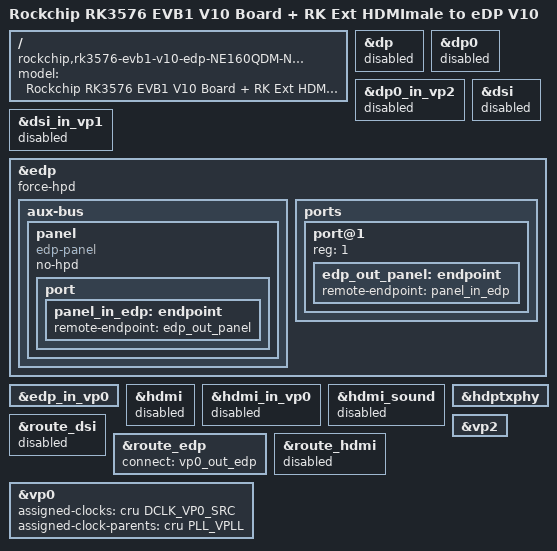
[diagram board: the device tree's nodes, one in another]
// SPDX-License-Identifier: (GPL-2.0+ OR MIT)
/*
 * Copyright (c) 2026 Rockchip Electronics Co., Ltd.
 *
 */

/dts-v1/;

#include "rk3576.dtsi"
#include "rk3576-evb1.dtsi"
#include "rk3576-evb1-cam-dcphy0.dtsi"
#include "rk3576-android.dtsi"

/ {
	model = "Rockchip RK3576 EVB1 V10 Board + RK Ext HDMImale to eDP V10";
	compatible = "rockchip,rk3576-evb1-v10-edp-NE160QDM-NY1", "rockchip,rk3576";
};

&dp {
	status = "disabled";
};

&dp0 {
	status = "disabled";
};

&dp0_in_vp2 {
	status = "disabled";
};

&dsi {
	status = "disabled";
};

&dsi_in_vp1 {
	status = "disabled";
};

&edp {
	force-hpd;
	status = "okay";

	aux-bus {
		panel {
			compatible = "edp-panel";
			no-hpd;

			port {
				panel_in_edp: endpoint {
					remote-endpoint = <&edp_out_panel>;
				};
			};
		};
	};

	ports {
		port@1 {
			reg = <1>;

			edp_out_panel: endpoint {
				remote-endpoint = <&panel_in_edp>;
			};
		};
	};
};

&edp_in_vp0 {
	status = "okay";
};

&hdmi {
	status = "disabled";
};

&hdmi_in_vp0 {
	status = "disabled";
};

&hdmi_sound {
	status = "disabled";
};

&hdptxphy {
	status = "okay";
};

&route_dsi {
	status = "disabled";
};

&route_edp {
	status = "okay";
	connect = <&vp0_out_edp>;
};

&route_hdmi {
	status = "disabled";
};

&vp0 {
	assigned-clocks = <&cru DCLK_VP0_SRC>;
	assigned-clock-parents = <&cru PLL_VPLL>;
};

&vp2 {
	/delete-property/ assigned-clocks;
	/delete-property/ assigned-clock-parents;
};
